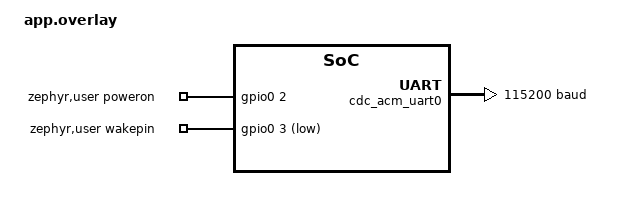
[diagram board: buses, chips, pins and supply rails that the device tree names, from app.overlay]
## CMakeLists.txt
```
cmake_minimum_required(VERSION 3.20.0)

set(BOARD rpi_pico)

find_package(Zephyr)
project(morpheus_app)

target_sources(app PRIVATE src/main.cpp src/generated.cpp src/protocol.cpp src/morpheus-states.cpp)
```

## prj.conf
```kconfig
CONFIG_CPLUSPLUS=y
CONFIG_GPIO=yes
CONFIG_SERIAL=yes
CONFIG_UART_INTERRUPT_DRIVEN=y
CONFIG_UART_LINE_CTRL=y

CONFIG_USB_DEVICE_STACK=y
CONFIG_USB_DEVICE_PRODUCT="Balena Morpheus Interface"
CONFIG_USB_CDC_ACM_RINGBUF_SIZE=512
CONFIG_HEAP_MEM_POOL_SIZE=2048
```

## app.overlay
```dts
/*
 * Copyright (c) 2021 Nordic Semiconductor ASA
 *
 * SPDX-License-Identifier: Apache-2.0
 */
#include <zephyr/dt-bindings/gpio/gpio.h>

&zephyr_udc0 {
	cdc_acm_uart0 {
		compatible = "zephyr,cdc-acm-uart";
		label = "CDC_ACM_0";
		parity = "none";
		current-speed = <115200>;
	};
};

/ { 
	zephyr,user {
    	poweron-gpios = <&gpio0 2 GPIO_ACTIVE_HIGH>;
		wakepin-gpios = <&gpio0 3 (GPIO_ACTIVE_LOW | GPIO_PULL_UP) >;
	};
};
```

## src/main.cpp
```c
/**
 * @file main.cpp
 * @author Aurelien VALADE (aurelien.valade@balena.io)
 * @brief Morpheus is a companion application to be run on co-processor micro-controller, disgned to manage SingleBoard Computers deep-sleep capabilities.
 * @version 0.1
 * @date 2022-06-22
 * 
 * @copyright Copyright (c) 2022 Balena io
 * 
 */


#include <zephyr/zephyr.h>
#include <zephyr/device.h>
#include <zephyr/drivers/gpio.h>
#include <zephyr/drivers/uart.h>
#include <zephyr/usb/usb_device.h>
#include <string.h>
#include "generated.h"
#include "protocol.h"
#include "morpheus-states.h"

/* 1000 msec = 1 sec */
#define SLEEP_TIME_MS   1000

/* The devicetree node identifier for the "led0" alias. */
#define MORPHEUS_USER_NODE DT_PATH(zephyr_user)

/*
 * A build error on this line means your board is unsupported.
 * See the sample documentation for information on how to fix this.
 */
static const struct device *uart = DEVICE_DT_GET_ONE(zephyr_cdc_acm_uart);


int main(void)
{
	int ret;
	char tx_buf[MORPHEUS_FRAME_SIZE];

    if (usb_enable(NULL) != 0){
		printk("Failed to enable USB");
		return 0;
	}
	
	if (!morpheus_protocol_init(uart))
		return 0;

	morpheus_state_init();

	while ( morpheus_protocol_get_frame(tx_buf)== 0) {
		
		void* params;
		Instructions inst = INST_SLEEPTIME;
		int size = tx_buf[0];

		if (parse_instruction_frame(tx_buf+1, size, &inst, &params) < 0)
		{
			s_fb_getversion_params version{.major = 0, .minor = 1, .patch = 99};
			ret = build_feedback_getversion_frame(tx_buf, &size, &version);
			morpheus_protocol_send_frame((const uint8_t*)tx_buf, size);
			continue;
		}
		
		switch (inst)
		{
		case INST_GETVERSION:
			{
				s_fb_getversion_params version{.major = 0, .minor = 1, .patch = 1};
				ret = build_feedback_getversion_frame(tx_buf, &size, &version);
				morpheus_protocol_send_frame((const uint8_t*)tx_buf, size);
				break;
			}

		case INST_SLEEPPIN:
			{
            	uint16_t delay = ((s_inst_sleeppin_params*) params)->pre_sleep_time;
				bool wake_state = ((s_inst_sleeppin_params*) params)->wake_pin_active_state;
				s_fb_sleeppin_params fb {.success = true};
				ret = build_feedback_sleeppin_frame(tx_buf, &size, &fb);
				morpheus_protocol_send_frame((const uint8_t*)tx_buf, size);

				morpheus_sleep_pin(delay, wake_state);
				break;
			}

		case INST_SLEEPTIME:
			{
            	uint16_t delay = ((s_inst_sleeptime_params*) params)->pre_sleep_time;
				uint32_t sleep_time = ((s_inst_sleeptime_params*) params)->duration;
				s_fb_sleeptime_params fb {.feedback = 1};
				ret = build_feedback_sleeptime_frame(tx_buf, &size, &fb);
				morpheus_protocol_send_frame((const uint8_t*)tx_buf, size);

				morpheus_sleep_time(delay, sleep_time);
				break;
			}
		
		default:
			{
				s_fb_getversion_params version{.major = 0, .minor = 1, .patch = 98};
				ret = build_feedback_getversion_frame(tx_buf, &size, &version);
				morpheus_protocol_send_frame((const uint8_t*)tx_buf, size);
				break;
			}
			break;
		}

		k_free(params);

	}
}
```

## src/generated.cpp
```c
// This file is autogenerated, please do not edit manually
#include <stdint.h>
#include <string.h>
#include <stdlib.h>

#include "generated.h"
#include <zephyr/zephyr.h>

int build_feedback_getversion_frame(char* buffer, int *len, struct s_fb_getversion_params* parameters)
{
    int position = 0;

    if ((buffer == NULL) || (len == NULL) || (parameters == NULL))
      return -1;
    
    if (position < *len) buffer[position++] = 0;
    else return -1;
        
    if (position < *len) buffer[position++] = (uint8_t) parameters->major;
    else return -1;
    

    if (position < *len) buffer[position++] = (uint8_t) parameters->minor;
    else return -1;
    

    if (position < *len) buffer[position++] = (uint8_t) parameters->patch;
    else return -1;
    
    *len = position;

    return 0;
}
        
int build_feedback_sleeppin_frame(char* buffer, int *len, struct s_fb_sleeppin_params* parameters)
{
    int position = 0;

    if ((buffer == NULL) || (len == NULL) || (parameters == NULL))
      return -1;
    
    if (position < *len) buffer[position++] = 3;
    else return -1;
        
    if (position < *len) buffer[position++] = (uint8_t) parameters->success;
    else return -1;
    
    *len = position;

    return 0;
}
        
int build_feedback_sleeptime_frame(char* buffer, int *len, struct s_fb_sleeptime_params* parameters)
{
    int position = 0;

    if ((buffer == NULL) || (len == NULL) || (parameters == NULL))
      return -1;
    
    if (position < *len) buffer[position++] = 4;
    else return -1;
        
    if (position < *len) buffer[position++] = (uint8_t) parameters->feedback;
    else return -1;
    
    *len = position;

    return 0;
}
        
int build_instruction_getversion_frame(char* buffer, int *len, struct s_inst_getversion_params* parameters)
{
    int position = 0;

    if ((buffer == NULL) || (len == NULL) || (parameters == NULL))
      return -1;
    
    if (position < *len) buffer[position++] = 0;
    else return -1;
        
    *len = position;

    return 0;
}
        
int build_instruction_sleeppin_frame(char* buffer, int *len, struct s_inst_sleeppin_params* parameters)
{
    int position = 0;

    if ((buffer == NULL) || (len == NULL) || (parameters == NULL))
      return -1;
    
    if (position < *len) buffer[position++] = 3;
    else return -1;
        
    if ((position + 2) < *len) {
        memcpy(&buffer[position], &parameters->pre_sleep_time, 2);
        position += 2;
    }
    else return -1;
    

    if (position < *len) buffer[position++] = (uint8_t) parameters->wake_pin_active_state;
    else return -1;
    
    *len = position;

    return 0;
}
        
int build_instruction_sleeptime_frame(char* buffer, int *len, struct s_inst_sleeptime_params* parameters)
{
    int position = 0;

    if ((buffer == NULL) || (len == NULL) || (parameters == NULL))
      return -1;
    
    if (position < *len) buffer[position++] = 4;
    else return -1;
        
    if ((position + 2) < *len) {
        memcpy(&buffer[position], &parameters->pre_sleep_time, 2);
        position += 2;
    }
    else return -1;
    

    if ((position + 4) < *len) {
        memcpy(&buffer[position], &parameters->duration, 4);
        position += 4;
    }
    else return -1;
    
    *len = position;

    return 0;
}
        
int parse_feedback_getversion_frame(char* buffer, int len, struct s_fb_getversion_params* parameters)
{
    int position = 0;
    const size_t p_size = sizeof(struct s_fb_getversion_params);


    if (buffer == NULL)
        return -1;

    if ((p_size > 0) && (parameters == NULL))
        return -1;
        
    // Check the code
    if (buffer[position++] != 0) return -1;
        
    if (position < len) parameters->major = (uint8_t) buffer[position++] ;
    else return -1;
    

    if (position < len) parameters->minor = (uint8_t) buffer[position++] ;
    else return -1;
    

    if (position < len) parameters->patch = (uint8_t) buffer[position++] ;
    else return -1;
    
    return 0;
}
        
int parse_feedback_sleeppin_frame(char* buffer, int len, struct s_fb_sleeppin_params* parameters)
{
    int position = 0;
    const size_t p_size = sizeof(struct s_fb_sleeppin_params);


    if (buffer == NULL)
        return -1;

    if ((p_size > 0) && (parameters == NULL))
        return -1;
        
    // Check the code
    if (buffer[position++] != 3) return -1;
        
    if (position < len) parameters->success = (buffer[position++] != 0) ;
    else return -1;
    
    return 0;
}
        
int parse_feedback_sleeptime_frame(char* buffer, int len, struct s_fb_sleeptime_params* parameters)
{
    int position = 0;
    const size_t p_size = sizeof(struct s_fb_sleeptime_params);


    if (buffer == NULL)
        return -1;

    if ((p_size > 0) && (parameters == NULL))
        return -1;
        
    // Check the code
    if (buffer[position++] != 4) return -1;
        
    if (position < len) parameters->feedback = (uint8_t) buffer[position++] ;
    else return -1;
    
    return 0;
}
        
int parse_instruction_getversion_frame(char* buffer, int len, struct s_inst_getversion_params* parameters)
{
    int position = 0;
    const size_t p_size = sizeof(struct s_inst_getversion_params);


    if (buffer == NULL)
        return -1;

    if ((p_size > 0) && (parameters == NULL))
        return -1;

    // Check the code
    if (buffer[position++] != 0) return -1;
        
    return 0;
}
        
int parse_instruction_sleeppin_frame(char* buffer, int len, struct s_inst_sleeppin_params* parameters)
{
    int position = 0;
    const size_t p_size = sizeof(struct s_inst_sleeppin_params);


    if (buffer == NULL)
        return -1;

    if ((p_size > 0) && (parameters == NULL))
        return -1;

    // Check the code
    if (buffer[position++] != 3) return -1;
        
    if ((position + 2) < len) {
        memcpy(&parameters->pre_sleep_time, &buffer[position], 2);
        position += 2;
    }
    else return -1;
    

    if (position < len) parameters->wake_pin_active_state = (buffer[position++] != 0);
    else return -1;
    
    return 0;
}
        
int parse_instruction_sleeptime_frame(char* buffer, int len, struct s_inst_sleeptime_params* parameters)
{
    int position = 0;
    const size_t p_size = sizeof(struct s_inst_sleeptime_params);


    if (buffer == NULL)
        return -1;

    if ((p_size > 0) && (parameters == NULL))
        return -1;

    // Check the code
    if (buffer[position++] != 4) return -1;
        
    if ((position + 2) < len) {
        memcpy(&parameters->pre_sleep_time, &buffer[position], 2);
        position += 2;
    }
    else return -1;
    

    if ((position + 4) < len) {
        memcpy(&parameters->duration, &buffer[position], 4);
        position += 4;
    }
    else return -1;
    
    return 0;
}
        
int parse_feedback_frame(char* buffer, int len, Feedbacks* code, void **parameters)
{
    if ((buffer == NULL) || (code == NULL) || (parameters == NULL))
        return -1;

    switch (buffer[0])
    {
    
        case 0:
            {
                const size_t psize = sizeof(struct s_fb_getversion_params);
                *parameters = k_malloc(psize);
                memset(*parameters, 0, psize);
                *code = FB_GETVERSION;
                return parse_feedback_getversion_frame(buffer, len, (struct s_fb_getversion_params*)*parameters);
            }
        
        case 3:
            {
                const size_t psize = sizeof(struct s_fb_sleeppin_params);
                *parameters = k_malloc(psize);
                memset(*parameters, 0, psize);
                *code = FB_SLEEPPIN;
                return parse_feedback_sleeppin_frame(buffer, len, (struct s_fb_sleeppin_params*)*parameters);
            }
        
        case 4:
            {
                const size_t psize = sizeof(struct s_fb_sleeptime_params);
                *parameters = k_malloc(psize);
                memset(*parameters, 0, psize);
                *code = FB_SLEEPTIME;
                return parse_feedback_sleeptime_frame(buffer, len, (struct s_fb_sleeptime_params*)*parameters);
            }
        
    default: 
        return -1;
    }
}

    
int parse_instruction_frame(char* buffer, int len, Instructions* code, void **parameters)
{
    if ((buffer == NULL) || (code == NULL) || (parameters == NULL))
        return -1;

    switch (buffer[0])
    {
    
        case 0:
            {
                const size_t psize = sizeof(struct s_inst_getversion_params);
                *parameters = k_malloc(psize);
                memset(*parameters, 0, psize);
                *code = INST_GETVERSION;
                return parse_instruction_getversion_frame(buffer, len, (struct s_inst_getversion_params*)*parameters);
            }
        
        case 3:
            {
                const size_t psize = sizeof(struct s_inst_sleeppin_params);
                *parameters = k_malloc(psize);
                memset(*parameters, 0, psize);
                *code = INST_SLEEPPIN;
                return parse_instruction_sleeppin_frame(buffer, len, (struct s_inst_sleeppin_params*)*parameters);
            }
        
        case 4:
            {
                const size_t psize = sizeof(struct s_inst_sleeptime_params);
                *parameters = k_malloc(psize);
                memset(*parameters, 0, psize);
                *code = INST_SLEEPTIME;
                return parse_instruction_sleeptime_frame(buffer, len, (struct s_inst_sleeptime_params*)*parameters);
            }
        
    default: 
        return -1;
    }
}

    
```

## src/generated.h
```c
// This file is autogenerated, please do not edit manually
#include <stdint.h>
#include <string.h>
#include <stdlib.h>


// Instructions Codes list
typedef enum __instructions_enum {
    INST_GETVERSION = 0,
	INST_SLEEPPIN = 3,
	INST_SLEEPTIME = 4
} Instructions;


// Feedback codes list
typedef enum __feedbacks_enum {
    FB_GETVERSION = 0,
	FB_SLEEPPIN = 3,
	FB_SLEEPTIME = 4
} Feedbacks;




struct s_inst_getversion_params {
    
};

struct s_inst_sleeppin_params {
    uint16_t pre_sleep_time;
	bool wake_pin_active_state;
};

struct s_inst_sleeptime_params {
    uint16_t pre_sleep_time;
	uint32_t duration;
};

struct s_fb_getversion_params {
    uint8_t major;
	uint8_t minor;
	uint8_t patch;
};
    
struct s_fb_sleeppin_params {
    bool success;
};
    
struct s_fb_sleeptime_params {
    uint8_t feedback;
};
    
int build_feedback_getversion_frame(char* buffer, int *len, struct s_fb_getversion_params* parameters);

int build_instruction_getversion_frame(char* buffer, int *len, struct s_inst_getversion_params* parameters);

int build_feedback_sleeppin_frame(char* buffer, int *len, struct s_fb_sleeppin_params* parameters);

int build_instruction_sleeppin_frame(char* buffer, int *len, struct s_inst_sleeppin_params* parameters);

int build_feedback_sleeptime_frame(char* buffer, int *len, struct s_fb_sleeptime_params* parameters);

int build_instruction_sleeptime_frame(char* buffer, int *len, struct s_inst_sleeptime_params* parameters);


    // External parsing functions
    extern int parse_feedback_frame(char* buffer, int len, Feedbacks* code, void **parameters);
    extern int parse_instruction_frame(char* buffer, int len, Instructions* code, void **parameters);
```

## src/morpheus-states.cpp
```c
#include <zephyr/zephyr.h>
#include <zephyr/device.h>
#include <zephyr/drivers/gpio.h>
#include <zephyr/kernel.h>
#include "morpheus-states.h"
#include <zephyr/usb/usb_device.h>

#define MORPHEUS_USER_NODE DT_PATH(zephyr_user)

#define LED0_NODE DT_ALIAS(led0)

static const struct gpio_dt_spec led = GPIO_DT_SPEC_GET(LED0_NODE, gpios);
static const struct gpio_dt_spec relay = GPIO_DT_SPEC_GET(MORPHEUS_USER_NODE, poweron_gpios); 
static const struct gpio_dt_spec wakepin = GPIO_DT_SPEC_GET(MORPHEUS_USER_NODE, wakepin_gpios);

/* Commands definition for the command queue */
enum MorpheusCommands {
    MSMC_NONE,
    MSMC_SLEEP_PIN,
    MSMC_SLEEP_TIME
};

/* Forward declaration of state table */
K_MSGQ_DEFINE(morpheus_cmdq, sizeof(MorpheusCommands), 2, 1);


/* Morpheus state object */
struct morpheus_s_object {
        /* Other state specific data add here */
        uint16_t pre_delay;
        bool wait_pin_state;
        uint32_t sleep_time;
} ms_obj;

/**
 * @brief Handle the SleepPin instruction routine
 * 
 * This function puts executes the SleepPin procedure:
 *   - Wait for PRE_DELAY seconds,
 *   - Cut the Pi power,
 *   - Wait for the GPIO input pin to reach WAIT_PIN_STATE level,
 *   - Wake up the Raspberry Pi,
 * 
 * NOTE: This function is blocking and should be executed in a separate thread.
 * 
 * @param pre_delay Duration (in seconds) to wait before cutting power
 * @param wait_pin_state Wake-up pin active state (true for high)
 */
static void __morpheus_sleep_pin_routine(uint16_t pre_delay, bool wait_pin_state)
{
    // Wait for the pre-sleep delay
    k_sleep(K_SECONDS(pre_delay));
    
    // Cut the power
    gpio_pin_set_dt(&relay, 0);
    gpio_pin_set_dt(&led, 0);

    // Wait for the GPIO to reach desired state
    while (gpio_pin_get_dt(&wakepin) == wait_pin_state)
    {
        k_sleep(K_MSEC(100));
    }

    // Restore the power
    gpio_pin_set_dt(&relay, 1);
    gpio_pin_set_dt(&led, 1);
}

/**
 * @brief Handle the SleepTime instruction routine
 * 
 * This function puts executes the SleepTime procedure:
 *   - Wait for PRE_DELAY seconds,
 *   - Cut the Pi power,
 *   - Wait for SLEEP_TIME seconds,
 *   - Wake up the Raspberry Pi,
 * 
 * NOTE: This function is blocking and should be executed in a separate thread.
 * 
 * @param pre_delay Duration (in seconds) to wait before cutting power
 * @param sleep_time Duration (in seconds) to wait before restoring power
 */
static void __morpheus_sleep_time_routine(uint16_t pre_delay, uint32_t sleep_time)
{
    // Wait for the pre-sleep delay
    k_sleep(K_SECONDS(pre_delay));
    
    // Cut the power
    gpio_pin_set_dt(&relay, 0);
    gpio_pin_set_dt(&led, 0);

    // Wait for the sleep-time delay
    k_sleep(K_SECONDS(sleep_time));

    // Restore the power
    gpio_pin_set_dt(&relay, 1);
    gpio_pin_set_dt(&led, 1);
}

/**
 * @brief Main Morpheus loop
 * 
 * This function fetches instructions from the command queue and starts the relevant routine.
 */
void morpheus_state_thread_entry(void*, void*, void*) {
    MorpheusCommands cmd = MSMC_NONE;

    while(1) {
        // Poll the commands
        if (k_msgq_get(&morpheus_cmdq, &cmd, K_SECONDS(1)) == 0)
        {
            switch (cmd) 
            {
            case MSMC_NONE:
                break;

            case MSMC_SLEEP_PIN:
                __morpheus_sleep_pin_routine(ms_obj.pre_delay, ms_obj.wait_pin_state);
                break;

            case MSMC_SLEEP_TIME:
                __morpheus_sleep_time_routine(ms_obj.pre_delay, ms_obj.sleep_time);
                break;
            
            default:
                break;
            }
        } 
    }
}

K_THREAD_STACK_DEFINE(morpheus_stack_area, 1024);
struct k_thread morpheus_thread_data;

void morpheus_state_init()
{
    /* Configure GPIOs */
   gpio_pin_configure_dt(&wakepin, GPIO_INPUT);
   gpio_pin_configure_dt(&relay, GPIO_OUTPUT_ACTIVE);
   gpio_pin_configure_dt(&led, GPIO_OUTPUT_ACTIVE);
   gpio_pin_set_dt(&relay, 1); /// Relay is active by default
   gpio_pin_set_dt(&led, 1); /// Relay is active by default

    // Set some default values
    ms_obj.pre_delay = 90;
    ms_obj.sleep_time=0;
    ms_obj.wait_pin_state = false;

    k_thread_create(&morpheus_thread_data, morpheus_stack_area,
        K_THREAD_STACK_SIZEOF(morpheus_stack_area),
        morpheus_state_thread_entry, NULL, NULL, NULL,
        4, 0, K_SECONDS(10));
}

void morpheus_sleep_pin(uint16_t pre_delay, bool pin_state)
{
    MorpheusCommands cmd = MSMC_SLEEP_PIN;
    ms_obj.wait_pin_state = pin_state;
    ms_obj.pre_delay = pre_delay;
    k_msgq_put(&morpheus_cmdq, &cmd, K_MSEC(100));
}

void morpheus_sleep_time(uint16_t pre_delay, uint32_t sleep_time)
{
    MorpheusCommands cmd = MSMC_SLEEP_TIME;
    ms_obj.sleep_time = sleep_time;
    ms_obj.pre_delay = pre_delay;
    k_msgq_put(&morpheus_cmdq, &cmd, K_MSEC(100));
}
```

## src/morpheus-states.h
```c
#ifndef __MORPHEUS_STATES__
#define __MORPHEUS_STATES__

#include <stdint.h>

void morpheus_state_init();
void morpheus_sleep_pin(uint16_t pre_delay, bool pin_state);
void morpheus_sleep_time(uint16_t pre_delay, uint32_t sleep_time);

#endif
```

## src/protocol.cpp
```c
/**
 * @file protocol.cpp
 * @author Aurelien VALADE (aurelien.valade@balena.io)
 * @brief Morpheus project UART protocol utilities module
 * @version 0.1
 * @date 2022-07-13
 * 
 * @copyright Copyright (c) 2022
 * 
 */
#include <zephyr/zephyr.h>
#include <zephyr/device.h>
#include <zephyr/drivers/uart.h>
#include "protocol.h"


typedef enum __morpheus_frame_decoding_state_machine_state{
  MFDSS_IDLE,
  MFDSS_HEADER2,
  MFDSS_HEADER_OK,
  MFDSS_READING,
  MFDSS_WAIT_CSUM
} MFDS_STATE;

/* queue to store up to 3 messages (aligned to 4-byte boundary) */
K_MSGQ_DEFINE(uart_msgq, MORPHEUS_FRAME_SIZE, 4, 1);
K_MSGQ_DEFINE(uart_sendmsgq, MORPHEUS_FRAME_SIZE, 4, 1);

/* receive buffer used in UART ISR callback */
static uint8_t rx_buf[MORPHEUS_FRAME_SIZE];
static int rx_buf_pos;
static uint8_t tx_int_buf[MORPHEUS_FRAME_SIZE];
static const struct device *uart_dev = NULL;

/*
 * Read characters from UART until line end is detected. Afterwards push the
 * data to the message queue.
 */
static void morpheus_protocol_serial_cb(const struct device *dev, void *user_data)
{
	uint8_t c;
	static MFDS_STATE state = MFDSS_IDLE;
	static uint8_t csum;
	static uint8_t size;
	// uint32_t dtr;

	if (!uart_irq_update(dev)) {
		return;
	}

	// uart_line_ctrl_get(uart, UART_LINE_CTRL_DTR, &dtr);
	// if (!dtr) return;

	while (uart_irq_rx_ready(dev)) {

		uart_fifo_read(dev, &c, 1);

		switch (state)
		{
		case MFDSS_IDLE:
			if (c == 0x55) {
				state = MFDSS_HEADER2;
			}
			break;
		
		case MFDSS_HEADER2:
			if (c == 0xAA) {
				state = MFDSS_HEADER_OK;
				csum = 0;
				rx_buf_pos = 0;
			}
			else if (c != 0x55) {
				state = MFDSS_IDLE;
			}
			break;

		case MFDSS_HEADER_OK:
		    state = MFDSS_READING;
			size = c;
		    rx_buf[rx_buf_pos++] = c;
			csum = c;
			break;
		
		case MFDSS_READING:
		    rx_buf[rx_buf_pos++] = c;
			csum += c;
			if ((rx_buf_pos + 3) >= size) {
				state = MFDSS_WAIT_CSUM;
			}
			break;

		case MFDSS_WAIT_CSUM:
		    if (csum == c) 
                k_msgq_put(&uart_msgq, &rx_buf, K_NO_WAIT);
				
			state = MFDSS_IDLE;
			break;

		default:
			break;
		}
	}


	if (uart_irq_tx_ready(dev)) {
		if (k_msgq_get(&uart_sendmsgq, &tx_int_buf, K_NO_WAIT) == 0)
		{
			uart_fifo_fill(dev, tx_int_buf, tx_int_buf[2]);
		}
		else
		   uart_irq_tx_disable(dev);   
	}
}

/**
 * @brief Requests to send a frame on the UART bus
 * 
 * @param buffer Buffer containing the frame to be sent
 * @param len lenght of the frame to send
 */
void morpheus_protocol_send_frame(const uint8_t* buffer, uint8_t len) {
	static uint8_t send_buffer[MORPHEUS_FRAME_SIZE];
	send_buffer[0] = 0x55;
	send_buffer[1] = 0xAA;
	send_buffer[2] = len+4;
	uint8_t csum = len+4;
	int i;

    if (uart_dev == NULL)
        return;

	for (i=0; i<len; i++) {
		csum += buffer[i];
		send_buffer[3+i] = buffer[i];
	}
	send_buffer[3+len] = csum;

	uint32_t dtr;
	uart_line_ctrl_get(uart_dev, UART_LINE_CTRL_DTR, &dtr);
	if (!dtr) return;

	k_msgq_put(&uart_sendmsgq, &send_buffer, K_NO_WAIT);
	uart_irq_tx_enable(uart_dev);
}

/**
 * @brief Initialize the uart bus to communicate with the master
 * 
 * @param dev pointer to the UART device to communicate through
 * @return int 1 if success, 0 otherwise.
 */
int morpheus_protocol_init(const struct device *dev)
{
	if (!device_is_ready(dev)) {
		printk("UART device not found!");
		return 0;
	}

    uart_dev = dev;

    /* configure interrupt and callback to receive data */
	uart_irq_callback_user_data_set(dev, morpheus_protocol_serial_cb, NULL);
	uart_irq_rx_enable(dev);

    return 1;
}

int morpheus_protocol_get_frame(char *buffer)
{
    return k_msgq_get(&uart_msgq, buffer, K_FOREVER);
}
```

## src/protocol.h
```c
/**
 * @file protocol.h
 * @author Aurelien VALADE (aurelien.valade@balena.io)
 * @brief Morpheus project UART protocol utilities module header file
 * @version 0.1
 * @date 2022-07-13
 * 
 * @copyright Copyright (c) 2022
 * 
 */
#ifndef __MORPHEUS_PROTOCOL_H__
#define __MORPHEUS_PROTOCOL_H__

#include <zephyr/zephyr.h>
#include <zephyr/device.h>

#define MORPHEUS_FRAME_SIZE 255

int morpheus_protocol_init(const struct device *dev);
void morpheus_protocol_send_frame(const uint8_t* buffer, uint8_t len);
int morpheus_protocol_get_frame(char *buffer);

#endif
```
